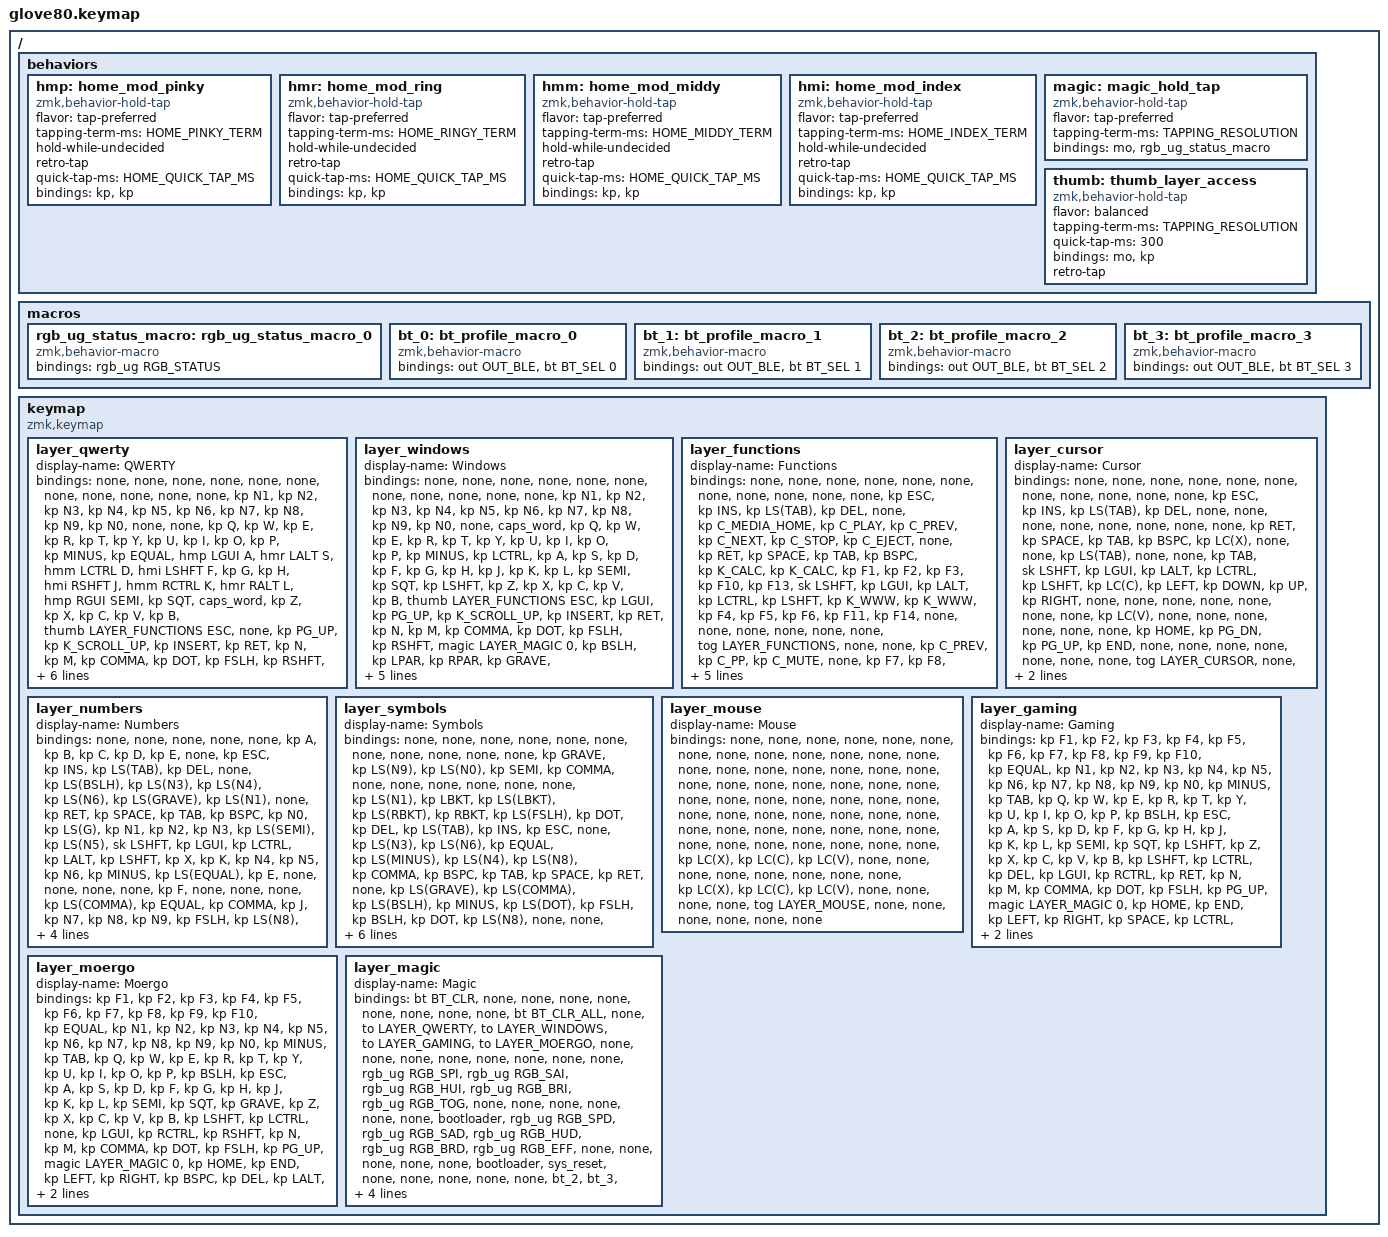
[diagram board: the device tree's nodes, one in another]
/*
* Copyright (c) 2020 The ZMK Contributors
*
* SPDX-License-Identifier: MIT
*/

#include <behaviors.dtsi>
#include <dt-bindings/zmk/bt.h>
#include <dt-bindings/zmk/ext_power.h>
#include <dt-bindings/zmk/keys.h>
#include <dt-bindings/zmk/outputs.h>
#include <dt-bindings/zmk/pointing.h>
#include <dt-bindings/zmk/rgb.h>

// layers
#define LAYER_QWERTY    0
#define LAYER_WINDOWS   1
#define LAYER_FUNCTIONS 2
#define LAYER_CURSOR    3
#define LAYER_NUMBERS   4
#define LAYER_SYMBOLS   5
#define LAYER_MOUSE     6
#define LAYER_GAMING    7
#define LAYER_MOERGO    8
#define LAYER_MAGIC     9

// prevent consecutive quick taps from being interpreted as holds
#define HOME_QUICK_TAP_MS 300

// TAPPING_RESOLUTION specifies the maximum speed (ms) at which the keyboard confuses
// your taps as being holds when typing on home row mod keys. Lower = faster detection.
#define TAPPING_RESOLUTION 150

// index finger: shortest reach, needs least time (default: 180)
#define HOME_INDEX_TERM 160
// middle finger: medium reach (default: 210)
#define HOME_MIDDY_TERM 210
// ring finger: longer reach (default: 240)
#define HOME_RINGY_TERM 240
// pinky finger: longest reach, needs most time (default: 270)
#define HOME_PINKY_TERM 270


/ {
  behaviors {
    // Home Row Mods
    hmp: home_mod_pinky {
      compatible = "zmk,behavior-hold-tap";
      #binding-cells = <2>;
      flavor = "tap-preferred";
      tapping-term-ms = <HOME_PINKY_TERM>;
      hold-while-undecided;
      retro-tap;
      quick-tap-ms = <HOME_QUICK_TAP_MS>;
      bindings = <&kp>, <&kp>;
    };
    hmr: home_mod_ring {
      compatible = "zmk,behavior-hold-tap";
      #binding-cells = <2>;
      flavor = "tap-preferred";
      tapping-term-ms = <HOME_RINGY_TERM>;
      hold-while-undecided;
      retro-tap;
      quick-tap-ms = <HOME_QUICK_TAP_MS>;
      bindings = <&kp>, <&kp>;
    };
    hmm: home_mod_middy {
      compatible = "zmk,behavior-hold-tap";
      #binding-cells = <2>;
      flavor = "tap-preferred";
      tapping-term-ms = <HOME_MIDDY_TERM>;
      hold-while-undecided;
      retro-tap;
      quick-tap-ms = <HOME_QUICK_TAP_MS>;
      bindings = <&kp>, <&kp>;
    };
    hmi: home_mod_index {
      compatible = "zmk,behavior-hold-tap";
      #binding-cells = <2>;
      flavor = "tap-preferred";
      tapping-term-ms = <HOME_INDEX_TERM>;
      hold-while-undecided;
      retro-tap;
      quick-tap-ms = <HOME_QUICK_TAP_MS>;
      bindings = <&kp>, <&kp>;
    };

    magic: magic_hold_tap {
      compatible = "zmk,behavior-hold-tap";
      #binding-cells = <2>;
      flavor = "tap-preferred";
      tapping-term-ms = <TAPPING_RESOLUTION>;
      bindings = <&mo>, <&rgb_ug_status_macro>;
    };

    // Thumb cluster hold-tap keys (from sunaku.keymap)
    thumb: thumb_layer_access {
      compatible = "zmk,behavior-hold-tap";
      flavor = "balanced";
      tapping-term-ms = <TAPPING_RESOLUTION>;
      quick-tap-ms = <300>;
      #binding-cells = <2>;
      bindings = <&mo>, <&kp>;
      retro-tap; // tap on standalone hold
    };
  };

  macros {
    rgb_ug_status_macro: rgb_ug_status_macro_0 {
      compatible = "zmk,behavior-macro";
      #binding-cells = <0>;
      bindings = <&rgb_ug RGB_STATUS>;
    };

    bt_0: bt_profile_macro_0 {
      compatible = "zmk,behavior-macro";
      #binding-cells = <0>;
      bindings = <&out OUT_BLE>, <&bt BT_SEL 0>;
    };

    bt_1: bt_profile_macro_1 {
      compatible = "zmk,behavior-macro";
      #binding-cells = <0>;
      bindings = <&out OUT_BLE>, <&bt BT_SEL 1>;
    };

    bt_2: bt_profile_macro_2 {
      compatible = "zmk,behavior-macro";
      #binding-cells = <0>;
      bindings = <&out OUT_BLE>, <&bt BT_SEL 2>;
    };

    bt_3: bt_profile_macro_3 {
      compatible = "zmk,behavior-macro";
      #binding-cells = <0>;
      bindings = <&out OUT_BLE>, <&bt BT_SEL 3>;
    };
  };

  keymap {
    compatible = "zmk,keymap";

    layer_qwerty {// Layer 0
      display-name = "QWERTY";
      bindings = <
//    ┌────────────────────────┬─────────────┬─────────────┬─────────────┬─────────────┐                                                                                                                                   ┌─────────────┬─────────────┬─────────────┬─────────────┬────────────────────────┐
//    │                        │             │             │             │             │                                                                                                                                   │             │             │             │             │                        │
//    ├────────────────────────┼─────────────┼─────────────┼─────────────┼─────────────┼───┐                                                                                                                           ┌───┼─────────────┼─────────────┼─────────────┼─────────────┼────────────────────────┤
//    │                        │      1      │      2      │      3      │      4      │ 5 │                                                                                                                           │ 6 │      7      │      8      │      9      │      0      │                        │
//    ├────────────────────────┼─────────────┼─────────────┼─────────────┼─────────────┼───┤                                                                                                                           ├───┼─────────────┼─────────────┼─────────────┼─────────────┼────────────────────────┤
//    │                        │      Q      │      W      │      E      │      R      │ T │                                                                                                                           │ Y │      U      │      I      │      O      │      P      │           -            │
//    ├────────────────────────┼─────────────┼─────────────┼─────────────┼─────────────┼───┤                                                                                                                           ├───┼─────────────┼─────────────┼─────────────┼─────────────┼────────────────────────┤
//    │           =            │ &hmp lgui A │ &hmr lalt S │ &hmm lctl D │ &hmi lsft F │ G │                                                                                                                           │ H │ &hmi rsft J │ &hmm rctl K │ &hmr ralt L │ &hmp rgui ; │           '            │
//    ├────────────────────────┼─────────────┼─────────────┼─────────────┼─────────────┼───┼──────────────────────────────┬──────────────────────────────┬──────┐   ┌─────────────┬─────┬──────────────────────────────┼───┼─────────────┼─────────────┼─────────────┼─────────────┼────────────────────────┤
//    │         capsw          │      Z      │      X      │      C      │      V      │ B │ &thumb laltYER_FUNCTIONS esc │                              │ pgup │   │ K_SCROLL_up │ ins │             ent              │ N │      M      │      ,      │      .      │      /      │          rsft          │
//    ├────────────────────────┼─────────────┼─────────────┼─────────────┼─────────────┼───┼──────────────────────────────┼──────────────────────────────┼──────┤   ├─────────────┼─────┼──────────────────────────────┼───┼─────────────┼─────────────┼─────────────┼─────────────┼────────────────────────┤
//    │ &magic laltYER_MAGIC 0 │      \      │      (      │      )      │      `      │   │ &thumb laltYER_CUrsftOR bspc │ &thumb laltYER_NUMBErsft del │ pgdn │   │ K_SCROLL_up │ tab │ &thumb laltYER_SYMBOlsft spc │   │             │      [      │      ]      │             │ &magic laltYER_MAGIC 0 │
//    └────────────────────────┴─────────────┴─────────────┴─────────────┴─────────────┘   └──────────────────────────────┴──────────────────────────────┴──────┘   └─────────────┴─────┴──────────────────────────────┘   └─────────────┴─────────────┴─────────────┴─────────────┴────────────────────────┘
  &none                  &none         &none         &none          &none                                                                                                                                                                &none          &none          &none         &none            &none
  &none                  &kp N1        &kp N2        &kp N3         &kp N4         &kp N5                                                                                                                                       &kp N6   &kp N7         &kp N8         &kp N9        &kp N0           &none
  &none                  &kp Q         &kp W         &kp E          &kp R          &kp T                                                                                                                                        &kp Y    &kp U          &kp I          &kp O         &kp P            &kp MINUS
  &kp EQUAL              &hmp LGUI A   &hmr LALT S   &hmm LCTRL D   &hmi LSHFT F   &kp G                                                                                                                                        &kp H    &hmi RSHFT J   &hmm RCTRL K   &hmr RALT L   &hmp RGUI SEMI   &kp SQT
  &caps_word             &kp Z         &kp X         &kp C          &kp V          &kp B    &thumb LAYER_FUNCTIONS ESC   &none                      &kp PG_UP       &kp K_SCROLL_UP   &kp INSERT   &kp RET                      &kp N    &kp M          &kp COMMA      &kp DOT       &kp FSLH         &kp RSHFT
  &magic LAYER_MAGIC 0   &kp BSLH      &kp LPAR      &kp RPAR       &kp GRAVE               &thumb LAYER_CURSOR BSPC     &thumb LAYER_NUMBERS DEL   &kp PG_DN       &kp K_SCROLL_UP   &kp TAB      &thumb LAYER_SYMBOLS SPACE            &none          &kp LBKT       &kp RBKT      &none            &magic LAYER_MAGIC 0
      >;
    };

    layer_windows {// Layer 1
      display-name = "Windows";
      bindings = <
//    ┌────────────────────────┬─────┬─────┬─────┬─────┐                                                                                                                                   ┌─────┬─────┬─────┬─────┬────────────────────────┐
//    │                        │     │     │     │     │                                                                                                                                   │     │     │     │     │                        │
//    ├────────────────────────┼─────┼─────┼─────┼─────┼───┐                                                                                                                           ┌───┼─────┼─────┼─────┼─────┼────────────────────────┤
//    │                        │  1  │  2  │  3  │  4  │ 5 │                                                                                                                           │ 6 │  7  │  8  │  9  │  0  │                        │
//    ├────────────────────────┼─────┼─────┼─────┼─────┼───┤                                                                                                                           ├───┼─────┼─────┼─────┼─────┼────────────────────────┤
//    │         capsw          │  Q  │  W  │  E  │  R  │ T │                                                                                                                           │ Y │  U  │  I  │  O  │  P  │           -            │
//    ├────────────────────────┼─────┼─────┼─────┼─────┼───┤                                                                                                                           ├───┼─────┼─────┼─────┼─────┼────────────────────────┤
//    │          lctl          │  A  │  S  │  D  │  F  │ G │                                                                                                                           │ H │  J  │  K  │  L  │  ;  │           '            │
//    ├────────────────────────┼─────┼─────┼─────┼─────┼───┼──────────────────────────────┬──────────────────────────────┬──────┐   ┌─────────────┬─────┬──────────────────────────────┼───┼─────┼─────┼─────┼─────┼────────────────────────┤
//    │          lsft          │  Z  │  X  │  C  │  V  │ B │ &thumb laltYER_FUNCTIONS esc │             lgui             │ pgup │   │ K_SCROLL_up │ ins │             ent              │ N │  M  │  ,  │  .  │  /  │          rsft          │
//    ├────────────────────────┼─────┼─────┼─────┼─────┼───┼──────────────────────────────┼──────────────────────────────┼──────┤   ├─────────────┼─────┼──────────────────────────────┼───┼─────┼─────┼─────┼─────┼────────────────────────┤
//    │ &magic laltYER_MAGIC 0 │  \  │  (  │  )  │  `  │   │ &thumb laltYER_CUrsftOR bspc │ &thumb laltYER_NUMBErsft del │ pgdn │   │ K_SCROLL_up │ tab │ &thumb laltYER_SYMBOlsft spc │   │     │  [  │  ]  │     │ &magic laltYER_MAGIC 0 │
//    └────────────────────────┴─────┴─────┴─────┴─────┘   └──────────────────────────────┴──────────────────────────────┴──────┘   └─────────────┴─────┴──────────────────────────────┘   └─────┴─────┴─────┴─────┴────────────────────────┘
  &none                  &none      &none      &none      &none                                                                                                                                                             &none    &none       &none      &none      &none
  &none                  &kp N1     &kp N2     &kp N3     &kp N4      &kp N5                                                                                                                                       &kp N6   &kp N7   &kp N8      &kp N9     &kp N0     &none
  &caps_word             &kp Q      &kp W      &kp E      &kp R       &kp T                                                                                                                                        &kp Y    &kp U    &kp I       &kp O      &kp P      &kp MINUS
  &kp LCTRL              &kp A      &kp S      &kp D      &kp F       &kp G                                                                                                                                        &kp H    &kp J    &kp K       &kp L      &kp SEMI   &kp SQT
  &kp LSHFT              &kp Z      &kp X      &kp C      &kp V       &kp B    &thumb LAYER_FUNCTIONS ESC   &kp LGUI                   &kp PG_UP       &kp K_SCROLL_UP   &kp INSERT   &kp RET                      &kp N    &kp M    &kp COMMA   &kp DOT    &kp FSLH   &kp RSHFT
  &magic LAYER_MAGIC 0   &kp BSLH   &kp LPAR   &kp RPAR   &kp GRAVE            &thumb LAYER_CURSOR BSPC     &thumb LAYER_NUMBERS DEL   &kp PG_DN       &kp K_SCROLL_UP   &kp TAB      &thumb LAYER_SYMBOLS SPACE            &none    &kp LBKT    &kp RBKT   &none      &magic LAYER_MAGIC 0
      >;
    };

    layer_functions {// Layer 2
      display-name = "Functions";
      bindings = <
//    ┌──────────┬──────┬──────┬───────────┬──────┐                                                                                      ┌─────────┬──────┬──────┬─────────┬──────────┐
//    │          │      │      │           │      │                                                                                      │         │      │      │         │          │
//    ├──────────┼──────┼──────┼───────────┼──────┼──────────┐                                                            ┌──────────────┼─────────┼──────┼──────┼─────────┼──────────┤
//    │          │ esc  │ ins  │ lsft(tab) │ del  │          │                                                            │ C_MEDIA_home │  play   │ prev │ next │  stop   │  eject   │
//    ├──────────┼──────┼──────┼───────────┼──────┼──────────┤                                                            ├──────────────┼─────────┼──────┼──────┼─────────┼──────────┤
//    │          │ ent  │ spc  │    tab    │ bspc │ K_CAlctl │                                                            │   K_CAlctl   │   f1    │  f2  │  f3  │   f10   │   f13    │
//    ├──────────┼──────┼──────┼───────────┼──────┼──────────┤                                                            ├──────────────┼─────────┼──────┼──────┼─────────┼──────────┤
//    │ &sk lsft │ lgui │ lalt │   lctl    │ lsft │  K_WWW   │                                                            │    K_WWW     │   f4    │  f5  │  f6  │   f11   │   f14    │
//    ├──────────┼──────┼──────┼───────────┼──────┼──────────┼───────────────────────┬─────┬─────┐   ┌──────┬──────┬──────┼──────────────┼─────────┼──────┼──────┼─────────┼──────────┤
//    │          │      │      │           │      │          │ tog laltYER_FUNCTIONS │     │     │   │ prev │ play │ mute │              │   f7    │  f8  │  f9  │   f12   │   f15    │
//    ├──────────┼──────┼──────┼───────────┼──────┼──────────┼───────────────────────┼─────┼─────┤   ├──────┼──────┼──────┼──────────────┼─────────┼──────┼──────┼─────────┼──────────┤
//    │          │      │      │           │      │          │                       │     │     │   │ next │ vold │ volu │              │ bri_max │ bri+ │ bri- │ bri_min │ bri_auto │
//    └──────────┴──────┴──────┴───────────┴──────┘          └───────────────────────┴─────┴─────┘   └──────┴──────┴──────┘              └─────────┴──────┴──────┴─────────┴──────────┘
  &none       &none      &none       &none         &none                                                                                                                             &none           &none          &none          &none           &none
  &none       &kp ESC    &kp INS     &kp LS(TAB)   &kp DEL     &none                                                                                              &kp C_MEDIA_HOME   &kp C_PLAY      &kp C_PREV     &kp C_NEXT     &kp C_STOP      &kp C_EJECT
  &none       &kp RET    &kp SPACE   &kp TAB       &kp BSPC    &kp K_CALC                                                                                         &kp K_CALC         &kp F1          &kp F2         &kp F3         &kp F10         &kp F13
  &sk LSHFT   &kp LGUI   &kp LALT    &kp LCTRL     &kp LSHFT   &kp K_WWW                                                                                          &kp K_WWW          &kp F4          &kp F5         &kp F6         &kp F11         &kp F14
  &none       &none      &none       &none         &none       &none        &tog LAYER_FUNCTIONS   &none   &none       &kp C_PREV   &kp C_PP       &kp C_MUTE     &none              &kp F7          &kp F8         &kp F9         &kp F12         &kp F15
  &none       &none      &none       &none         &none                    &none                  &none   &none       &kp C_NEXT   &kp C_VOL_DN   &kp C_VOL_UP                      &kp C_BRI_MAX   &kp C_BRI_UP   &kp C_BRI_DN   &kp C_BRI_MIN   &kp C_BRI_AUTO
      >;
    };

    layer_cursor {// Layer 3
      display-name = "Cursor";
      bindings = <
//    ┌──────────┬──────┬──────┬───────────┬──────┐                                                                         ┌──────┬───────────┬──────┬─────┬─────┐
//    │          │      │      │           │      │                                                                         │      │           │      │     │     │
//    ├──────────┼──────┼──────┼───────────┼──────┼─────────┐                                                        ┌──────┼──────┼───────────┼──────┼─────┼─────┤
//    │          │ esc  │ ins  │ lsft(tab) │ del  │         │                                                        │      │      │           │      │     │     │
//    ├──────────┼──────┼──────┼───────────┼──────┼─────────┤                                                        ├──────┼──────┼───────────┼──────┼─────┼─────┤
//    │          │ ent  │ spc  │    tab    │ bspc │ lctl(X) │                                                        │      │      │ lsft(tab) │      │     │ tab │
//    ├──────────┼──────┼──────┼───────────┼──────┼─────────┤                                                        ├──────┼──────┼───────────┼──────┼─────┼─────┤
//    │ &sk lsft │ lgui │ lalt │   lctl    │ lsft │ lctl(C) │                                                        │ left │ down │    up     │ rght │     │     │
//    ├──────────┼──────┼──────┼───────────┼──────┼─────────┼──────────────────────┬─────┬─────┐   ┌─────┬─────┬─────┼──────┼──────┼───────────┼──────┼─────┼─────┤
//    │          │      │      │           │      │ lctl(V) │                      │     │     │   │     │     │     │ home │ pgdn │   pgup    │ end  │     │     │
//    ├──────────┼──────┼──────┼───────────┼──────┼─────────┼──────────────────────┼─────┼─────┤   ├─────┼─────┼─────┼──────┼──────┼───────────┼──────┼─────┼─────┤
//    │          │      │      │           │      │         │ tog laltYER_CUrsftOR │     │     │   │     │     │     │      │      │           │      │     │     │
//    └──────────┴──────┴──────┴───────────┴──────┘         └──────────────────────┴─────┴─────┘   └─────┴─────┴─────┘      └──────┴───────────┴──────┴─────┴─────┘
  &none       &none      &none       &none         &none                                                                                              &none       &none         &none       &none   &none
  &none       &kp ESC    &kp INS     &kp LS(TAB)   &kp DEL     &none                                                                       &none      &none       &none         &none       &none   &none
  &none       &kp RET    &kp SPACE   &kp TAB       &kp BSPC    &kp LC(X)                                                                   &none      &none       &kp LS(TAB)   &none       &none   &kp TAB
  &sk LSHFT   &kp LGUI   &kp LALT    &kp LCTRL     &kp LSHFT   &kp LC(C)                                                                   &kp LEFT   &kp DOWN    &kp UP        &kp RIGHT   &none   &none
  &none       &none      &none       &none         &none       &kp LC(V)   &none               &none   &none       &none   &none   &none   &kp HOME   &kp PG_DN   &kp PG_UP     &kp END     &none   &none
  &none       &none      &none       &none         &none                   &tog LAYER_CURSOR   &none   &none       &none   &none   &none              &none       &none         &none       &none   &none
      >;
    };

    layer_numbers {// Layer 4
      display-name = "Numbers";
      bindings = <
//    ┌──────────┬──────┬──────┬───────────┬──────┐                                                                         ┌─────────┬─────────┬─────────┬─────────┬─────────┐
//    │          │      │      │           │      │                                                                         │    A    │    B    │    C    │    D    │    E    │
//    ├──────────┼──────┼──────┼───────────┼──────┼─────┐                                                         ┌─────────┼─────────┼─────────┼─────────┼─────────┼─────────┤
//    │          │ esc  │ ins  │ lsft(tab) │ del  │     │                                                         │ lsft(\) │ lsft(3) │ lsft(4) │ lsft(6) │ lsft(`) │ lsft(1) │
//    ├──────────┼──────┼──────┼───────────┼──────┼─────┤                                                         ├─────────┼─────────┼─────────┼─────────┼─────────┼─────────┤
//    │          │ ent  │ spc  │    tab    │ bspc │  0  │                                                         │ lsft(G) │    1    │    2    │    3    │ lsft(;) │ lsft(5) │
//    ├──────────┼──────┼──────┼───────────┼──────┼─────┤                                                         ├─────────┼─────────┼─────────┼─────────┼─────────┼─────────┤
//    │ &sk lsft │ lgui │ lctl │   lalt    │ lsft │  X  │                                                         │    K    │    4    │    5    │    6    │    -    │ lsft(=) │
//    ├──────────┼──────┼──────┼───────────┼──────┼─────┼─────┬───────────────────────┬─────┐   ┌─────────┬───┬───┼─────────┼─────────┼─────────┼─────────┼─────────┼─────────┤
//    │    E     │      │      │           │      │  F  │     │                       │     │   │ lsft(,) │ = │ , │    J    │    7    │    8    │    9    │    /    │ lsft(8) │
//    ├──────────┼──────┼──────┼───────────┼──────┼─────┼─────┼───────────────────────┼─────┤   ├─────────┼───┼───┼─────────┼─────────┼─────────┼─────────┼─────────┼─────────┤
//    │ lsft(-)  │      │      │           │      │     │     │ tog laltYER_NUMBErsft │     │   │ lsft(.) │ . │ 0 │         │ lsft(9) │    [    │    ]    │ lsft(0) │ lsft(2) │
//    └──────────┴──────┴──────┴───────────┴──────┘     └─────┴───────────────────────┴─────┘   └─────────┴───┴───┘         └─────────┴─────────┴─────────┴─────────┴─────────┘
  &none           &none      &none       &none         &none                                                                                                                &kp A        &kp B        &kp C        &kp D           &kp E
  &none           &kp ESC    &kp INS     &kp LS(TAB)   &kp DEL     &none                                                                                     &kp LS(BSLH)   &kp LS(N3)   &kp LS(N4)   &kp LS(N6)   &kp LS(GRAVE)   &kp LS(N1)
  &none           &kp RET    &kp SPACE   &kp TAB       &kp BSPC    &kp N0                                                                                    &kp LS(G)      &kp N1       &kp N2       &kp N3       &kp LS(SEMI)    &kp LS(N5)
  &sk LSHFT       &kp LGUI   &kp LCTRL   &kp LALT      &kp LSHFT   &kp X                                                                                     &kp K          &kp N4       &kp N5       &kp N6       &kp MINUS       &kp LS(EQUAL)
  &kp E           &none      &none       &none         &none       &kp F    &none   &none                &none       &kp LS(COMMA)   &kp EQUAL   &kp COMMA   &kp J          &kp N7       &kp N8       &kp N9       &kp FSLH        &kp LS(N8)
  &kp LS(MINUS)   &none      &none       &none         &none                &none   &tog LAYER_NUMBERS   &none       &kp LS(DOT)     &kp DOT     &kp N0                     &kp LS(N9)   &kp LBKT     &kp RBKT     &kp LS(N0)      &kp LS(N2)
      >;
    };

    layer_symbols {// Layer 5
      display-name = "Symbols";
      bindings = <
//    ┌─────────┬─────────┬─────────┬─────────┬─────────┐                                                                                     ┌─────────┬───────────┬──────┬──────┬─────┐
//    │         │         │         │         │         │                                                                                     │         │           │      │      │     │
//    ├─────────┼─────────┼─────────┼─────────┼─────────┼─────────┐                                                                     ┌─────┼─────────┼───────────┼──────┼──────┼─────┤
//    │         │    `    │ lsft(9) │ lsft(0) │    ;    │    ,    │                                                                     │     │         │           │      │      │     │
//    ├─────────┼─────────┼─────────┼─────────┼─────────┼─────────┤                                                                     ├─────┼─────────┼───────────┼──────┼──────┼─────┤
//    │ lsft(1) │    [    │ lsft([) │ lsft(]) │    ]    │ lsft(/) │                                                                     │  .  │   del   │ lsft(tab) │ ins  │ esc  │     │
//    ├─────────┼─────────┼─────────┼─────────┼─────────┼─────────┤                                                                     ├─────┼─────────┼───────────┼──────┼──────┼─────┤
//    │ lsft(3) │ lsft(6) │    =    │ lsft(-) │ lsft(4) │ lsft(8) │                                                                     │  ,  │  bspc   │    tab    │ spc  │ ent  │     │
//    ├─────────┼─────────┼─────────┼─────────┼─────────┼─────────┼─────────┬─────────┬─────────┐   ┌─────┬─────┬───────────────────────┼─────┼─────────┼───────────┼──────┼──────┼─────┤
//    │ lsft(`) │ lsft(,) │ lsft(\) │    -    │ lsft(.) │    /    │    \    │    .    │ lsft(8) │   │     │     │                       │  ;  │ lsft(') │     '     │  `   │  \   │     │
//    ├─────────┼─────────┼─────────┼─────────┼─────────┼─────────┼─────────┼─────────┼─────────┤   ├─────┼─────┼───────────────────────┼─────┼─────────┼───────────┼──────┼──────┼─────┤
//    │         │ lsft(7) │    '    │ lsft(') │ lsft(=) │         │ lsft(5) │ lsft(;) │ lsft(2) │   │     │     │ tog laltYER_SYMBOlsft │     │  rsft   │   rctl    │ ralt │ rgui │     │
//    └─────────┴─────────┴─────────┴─────────┴─────────┘         └─────────┴─────────┴─────────┘   └─────┴─────┴───────────────────────┘     └─────────┴───────────┴──────┴──────┴─────┘
  &none           &none           &none          &none           &none                                                                                                                        &none                  &none         &none       &none      &none
  &none           &kp GRAVE       &kp LS(N9)     &kp LS(N0)      &kp SEMI        &kp COMMA                                                                                        &none       &none                  &none         &none       &none      &none
  &kp LS(N1)      &kp LBKT        &kp LS(LBKT)   &kp LS(RBKT)    &kp RBKT        &kp LS(FSLH)                                                                                     &kp DOT     &kp DEL                &kp LS(TAB)   &kp INS     &kp ESC    &none
  &kp LS(N3)      &kp LS(N6)      &kp EQUAL      &kp LS(MINUS)   &kp LS(N4)      &kp LS(N8)                                                                                       &kp COMMA   &kp BSPC               &kp TAB       &kp SPACE   &kp RET    &none
  &kp LS(GRAVE)   &kp LS(COMMA)   &kp LS(BSLH)   &kp MINUS       &kp LS(DOT)     &kp FSLH       &kp BSLH     &kp DOT        &kp LS(N8)       &none   &none   &none                &kp SEMI    &kp LS(SINGLE_QUOTE)   &kp SQT       &kp GRAVE   &kp BSLH   &trans
  &none           &kp LS(N7)      &kp SQT        &kp LS(SQT)     &kp LS(EQUAL)                  &kp LS(N5)   &kp LS(SEMI)   &kp LS(N2)       &none   &none   &tog LAYER_SYMBOLS               &kp RSHFT              &kp RCTRL     &kp RALT    &kp RGUI   &none
      >;
    };

    layer_mouse {// Layer 6
      display-name = "Mouse";
      bindings = <
//    ┌─────┬─────┬─────────┬─────────┬─────────┐                                                                         ┌─────┬─────┬─────┬─────┬─────┐
//    │     │     │         │         │         │                                                                         │     │     │     │     │     │
//    ├─────┼─────┼─────────┼─────────┼─────────┼─────┐                                                             ┌─────┼─────┼─────┼─────┼─────┼─────┤
//    │     │     │         │         │         │     │                                                             │     │     │     │     │     │     │
//    ├─────┼─────┼─────────┼─────────┼─────────┼─────┤                                                             ├─────┼─────┼─────┼─────┼─────┼─────┤
//    │     │     │         │         │         │     │                                                             │     │     │     │     │     │     │
//    ├─────┼─────┼─────────┼─────────┼─────────┼─────┤                                                             ├─────┼─────┼─────┼─────┼─────┼─────┤
//    │     │     │         │         │         │     │                                                             │     │     │     │     │     │     │
//    ├─────┼─────┼─────────┼─────────┼─────────┼─────┼─────┬─────┬─────┐   ┌─────────┬───────────────────┬─────────┼─────┼─────┼─────┼─────┼─────┼─────┤
//    │     │     │         │         │         │     │     │     │     │   │ lctl(X) │      lctl(C)      │ lctl(V) │     │     │     │     │     │     │
//    ├─────┼─────┼─────────┼─────────┼─────────┼─────┼─────┼─────┼─────┤   ├─────────┼───────────────────┼─────────┼─────┼─────┼─────┼─────┼─────┼─────┤
//    │     │     │ lctl(X) │ lctl(C) │ lctl(V) │     │     │     │     │   │         │ tog laltYER_MOUSE │         │     │     │     │     │     │     │
//    └─────┴─────┴─────────┴─────────┴─────────┘     └─────┴─────┴─────┘   └─────────┴───────────────────┴─────────┘     └─────┴─────┴─────┴─────┴─────┘
  &none   &none   &none       &none       &none                                                                                              &none   &none   &none   &none   &none
  &none   &none   &none       &none       &none       &none                                                                          &none   &none   &none   &none   &none   &none
  &none   &none   &none       &none       &none       &none                                                                          &none   &none   &none   &none   &none   &none
  &none   &none   &none       &none       &none       &none                                                                          &none   &none   &none   &none   &none   &none
  &none   &none   &none       &none       &none       &none   &none   &none   &none       &kp LC(X)   &kp LC(C)          &kp LC(V)   &none   &none   &none   &none   &none   &none
  &none   &none   &kp LC(X)   &kp LC(C)   &kp LC(V)           &none   &none   &none       &none       &tog LAYER_MOUSE   &none               &none   &none   &none   &none   &none
      >;
    };

    layer_gaming {// Layer 7
      display-name = "Gaming";
   bindings = <
//    ┌────────────────────────┬──────┬─────┬──────┬──────┐                                                    ┌────┬──────┬────┬────┬──────┐
//    │           f1           │  f2  │ f3  │  f4  │  f5  │                                                    │ f6 │  f7  │ f8 │ f9 │ f10  │
//    ├────────────────────────┼──────┼─────┼──────┼──────┼───┐                                            ┌───┼────┼──────┼────┼────┼──────┤
//    │           =            │  1   │  2  │  3   │  4   │ 5 │                                            │ 6 │ 7  │  8   │ 9  │ 0  │  -   │
//    ├────────────────────────┼──────┼─────┼──────┼──────┼───┤                                            ├───┼────┼──────┼────┼────┼──────┤
//    │          tab           │  Q   │  W  │  E   │  R   │ T │                                            │ Y │ U  │  I   │ O  │ P  │  \   │
//    ├────────────────────────┼──────┼─────┼──────┼──────┼───┤                                            ├───┼────┼──────┼────┼────┼──────┤
//    │          esc           │  A   │  S  │  D   │  F   │ G │                                            │ H │ J  │  K   │ L  │ ;  │  '   │
//    ├────────────────────────┼──────┼─────┼──────┼──────┼───┼──────┬──────┬─────┐   ┌──────┬──────┬──────┼───┼────┼──────┼────┼────┼──────┤
//    │          lsft          │  Z   │  X  │  C   │  V   │ B │ lsft │ lctl │ del │   │ lgui │ rctl │ ent  │ N │ M  │  ,   │ .  │ /  │ pgup │
//    ├────────────────────────┼──────┼─────┼──────┼──────┼───┼──────┼──────┼─────┤   ├──────┼──────┼──────┼───┼────┼──────┼────┼────┼──────┤
//    │ &magic laltYER_MAGIC 0 │ home │ end │ left │ rght │   │ spc  │ lctl │ esc │   │ ralt │ tab  │ bspc │   │ up │ down │ [  │ ]  │ pgdn │
//    └────────────────────────┴──────┴─────┴──────┴──────┘   └──────┴──────┴─────┘   └──────┴──────┴──────┘   └────┴──────┴────┴────┴──────┘
  &kp F1                 &kp F2     &kp F3    &kp F4     &kp F5                                                                                                &kp F6   &kp F7      &kp F8     &kp F9     &kp F10
  &kp EQUAL              &kp N1     &kp N2    &kp N3     &kp N4      &kp N5                                                                           &kp N6   &kp N7   &kp N8      &kp N9     &kp N0     &kp MINUS
  &kp TAB                &kp Q      &kp W     &kp E      &kp R       &kp T                                                                            &kp Y    &kp U    &kp I       &kp O      &kp P      &kp BSLH
  &kp ESC                &kp A      &kp S     &kp D      &kp F       &kp G                                                                            &kp H    &kp J    &kp K       &kp L      &kp SEMI   &kp SQT
  &kp LSHFT              &kp Z      &kp X     &kp C      &kp V       &kp B    &kp LSHFT   &kp LCTRL   &kp DEL       &kp LGUI   &kp RCTRL   &kp RET    &kp N    &kp M    &kp COMMA   &kp DOT    &kp FSLH   &kp PG_UP
  &magic LAYER_MAGIC 0   &kp HOME   &kp END   &kp LEFT   &kp RIGHT            &kp SPACE   &kp LCTRL   &kp ESC       &kp RALT   &kp TAB     &kp BSPC            &kp UP   &kp DOWN    &kp LBKT   &kp RBKT   &kp PG_DN
            >;
    };

    layer_moergo {// Layer 8
      display-name = "Moergo";
   bindings = <
//    ┌────────────────────────┬──────┬─────┬──────┬──────┐                                                     ┌────┬──────┬────┬────┬──────┐
//    │           f1           │  f2  │ f3  │  f4  │  f5  │                                                     │ f6 │  f7  │ f8 │ f9 │ f10  │
//    ├────────────────────────┼──────┼─────┼──────┼──────┼───┐                                             ┌───┼────┼──────┼────┼────┼──────┤
//    │           =            │  1   │  2  │  3   │  4   │ 5 │                                             │ 6 │ 7  │  8   │ 9  │ 0  │  -   │
//    ├────────────────────────┼──────┼─────┼──────┼──────┼───┤                                             ├───┼────┼──────┼────┼────┼──────┤
//    │          tab           │  Q   │  W  │  E   │  R   │ T │                                             │ Y │ U  │  I   │ O  │ P  │  \   │
//    ├────────────────────────┼──────┼─────┼──────┼──────┼───┤                                             ├───┼────┼──────┼────┼────┼──────┤
//    │          esc           │  A   │  S  │  D   │  F   │ G │                                             │ H │ J  │  K   │ L  │ ;  │  '   │
//    ├────────────────────────┼──────┼─────┼──────┼──────┼───┼──────┬──────┬──────┐   ┌──────┬──────┬──────┼───┼────┼──────┼────┼────┼──────┤
//    │           `            │  Z   │  X  │  C   │  V   │ B │ lsft │ lctl │      │   │ lgui │ rctl │ rsft │ N │ M  │  ,   │ .  │ /  │ pgup │
//    ├────────────────────────┼──────┼─────┼──────┼──────┼───┼──────┼──────┼──────┤   ├──────┼──────┼──────┼───┼────┼──────┼────┼────┼──────┤
//    │ &magic laltYER_MAGIC 0 │ home │ end │ left │ rght │   │ bspc │ del  │ lalt │   │ ralt │ ent  │ spc  │   │ up │ down │ [  │ ]  │ pgdn │
//    └────────────────────────┴──────┴─────┴──────┴──────┘   └──────┴──────┴──────┘   └──────┴──────┴──────┘   └────┴──────┴────┴────┴──────┘
  &kp F1                 &kp F2     &kp F3    &kp F4     &kp F5                                                                                                  &kp F6   &kp F7      &kp F8     &kp F9     &kp F10
  &kp EQUAL              &kp N1     &kp N2    &kp N3     &kp N4      &kp N5                                                                             &kp N6   &kp N7   &kp N8      &kp N9     &kp N0     &kp MINUS
  &kp TAB                &kp Q      &kp W     &kp E      &kp R       &kp T                                                                              &kp Y    &kp U    &kp I       &kp O      &kp P      &kp BSLH
  &kp ESC                &kp A      &kp S     &kp D      &kp F       &kp G                                                                              &kp H    &kp J    &kp K       &kp L      &kp SEMI   &kp SQT
  &kp GRAVE              &kp Z      &kp X     &kp C      &kp V       &kp B    &kp LSHFT   &kp LCTRL   &none          &kp LGUI   &kp RCTRL   &kp RSHFT   &kp N    &kp M    &kp COMMA   &kp DOT    &kp FSLH   &kp PG_UP
  &magic LAYER_MAGIC 0   &kp HOME   &kp END   &kp LEFT   &kp RIGHT            &kp BSPC    &kp DEL     &kp LALT       &kp RALT   &kp RET     &kp SPACE            &kp UP   &kp DOWN    &kp LBKT   &kp RBKT   &kp PG_DN
            >;
    };

    layer_magic {// Layer 9
      display-name = "Magic";
      bindings = <
//    ┌────────────┬───────────────────┬────────────────────┬───────────────────┬─────────────────────┐                                                                ┌─────┬─────┬─────┬─────┬────────────┐
//    │   bt_clr   │                   │                    │                   │                     │                                                                │     │     │     │     │ bt_clr_ALL │
//    ├────────────┼───────────────────┼────────────────────┼───────────────────┼─────────────────────┼─────────┐                                                ┌─────┼─────┼─────┼─────┼─────┼────────────┤
//    │            │ to laltYER_QWERTY │ to laltYER_WINDOWS │ to laltYER_GAMING │ to laltYER_MOErguiO │         │                                                │     │     │     │     │     │            │
//    ├────────────┼───────────────────┼────────────────────┼───────────────────┼─────────────────────┼─────────┤                                                ├─────┼─────┼─────┼─────┼─────┼────────────┤
//    │            │      ug_ sp+      │      ug_ sa+       │      ug_ hu+      │       ug_ br+       │ ug_ tog │                                                │     │     │     │     │     │            │
//    ├────────────┼───────────────────┼────────────────────┼───────────────────┼─────────────────────┼─────────┤                                                ├─────┼─────┼─────┼─────┼─────┼────────────┤
//    │    boot    │      ug_ sp-      │      ug_ sa-       │      ug_ hu-      │       ug_ br-       │ ug_ eff │                                                │     │     │     │     │     │    boot    │
//    ├────────────┼───────────────────┼────────────────────┼───────────────────┼─────────────────────┼─────────┼───────┬───────┬──────────┐   ┌─────┬─────┬─────┼─────┼─────┼─────┼─────┼─────┼────────────┤
//    │ &sys_reset │                   │                    │                   │                     │         │ &bt_2 │ &bt_3 │          │   │     │     │     │     │     │     │     │     │ &sys_reset │
//    ├────────────┼───────────────────┼────────────────────┼───────────────────┼─────────────────────┼─────────┼───────┼───────┼──────────┤   ├─────┼─────┼─────┼─────┼─────┼─────┼─────┼─────┼────────────┤
//    │            │                   │                    │                   │                     │         │ &bt_0 │ &bt_1 │ out_ usb │   │     │     │     │     │     │     │     │     │            │
//    └────────────┴───────────────────┴────────────────────┴───────────────────┴─────────────────────┘         └───────┴───────┴──────────┘   └─────┴─────┴─────┘     └─────┴─────┴─────┴─────┴────────────┘
  &bt BT_CLR    &none              &none               &none              &none                                                                                                   &none   &none   &none   &none   &bt BT_CLR_ALL
  &none         &to LAYER_QWERTY   &to LAYER_WINDOWS   &to LAYER_GAMING   &to LAYER_MOERGO   &none                                                                        &none   &none   &none   &none   &none   &none
  &none         &rgb_ug RGB_SPI    &rgb_ug RGB_SAI     &rgb_ug RGB_HUI    &rgb_ug RGB_BRI    &rgb_ug RGB_TOG                                                              &none   &none   &none   &none   &none   &none
  &bootloader   &rgb_ug RGB_SPD    &rgb_ug RGB_SAD     &rgb_ug RGB_HUD    &rgb_ug RGB_BRD    &rgb_ug RGB_EFF                                                              &none   &none   &none   &none   &none   &bootloader
  &sys_reset    &none              &none               &none              &none              &none             &bt_2   &bt_3   &none              &none   &none   &none   &none   &none   &none   &none   &none   &sys_reset
  &none         &none              &none               &none              &none                                &bt_0   &bt_1   &out OUT_USB       &none   &none   &none           &none   &none   &none   &none   &none
      >;
    };
  };
};
